# rCSL_rtc_001 register map
Vendor: Texas Instruments
Peripheral module from a debugger description file (folder OMAPL138_C6748).
Registers are 32-bit, access not given, reset 0x0 unless marked. A register's access mark holds for its fields unless they carry their own. Offsets are as the file gives them; lines under a group give offsets from that group; [hi:lo] are bit positions; {n}, {i} and the like mark numbered series; 'fields as' and 'values as' point back to an identical list; <NAME> marks a mode.

## RTC
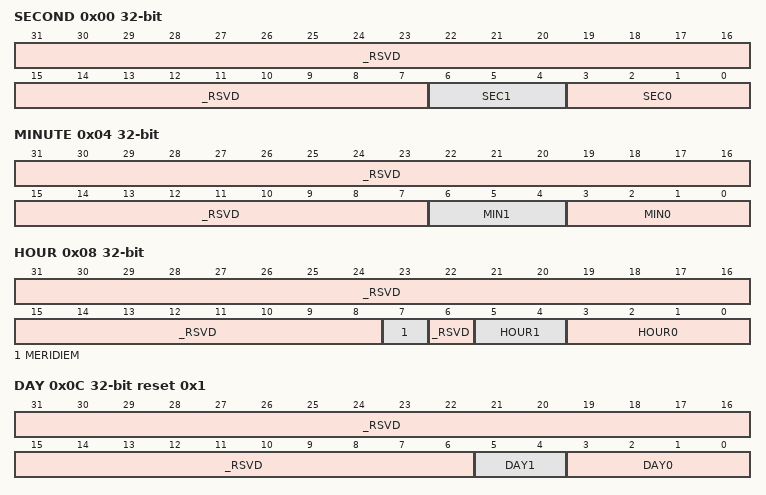
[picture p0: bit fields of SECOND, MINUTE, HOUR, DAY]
0x00 SECOND — Seconds Register
  [31:7] _RSVD — (access N)
  [6:4] SEC1 rw — 2nd digit of seconds
  [3:0] SEC0 rw — 1st digit of seconds
0x04 MINUTE — Minutes Register
  [31:7] _RSVD — (access N)
  [6:4] MIN1 rw — 2nd digit of minutes
  [3:0] MIN0 rw — 1st digit of minutes
0x08 HOUR — Hours Register
  [31:8] _RSVD — (access N)
  [7] MERIDIEM rw — PM or AM when PM_AM enabled
    0=AM; 1=PM
  [6] _RSVD — (access N)
  [5:4] HOUR1 rw — 2nd digit of hours
  [3:0] HOUR0 rw — 1st digit of hours
0x0C DAY reset 0x1 — Days Register
  [31:6] _RSVD — (access N)
  [5:4] DAY1 rw — 2nd digit of days
  [3:0] DAY0 rw — 1st digit of days
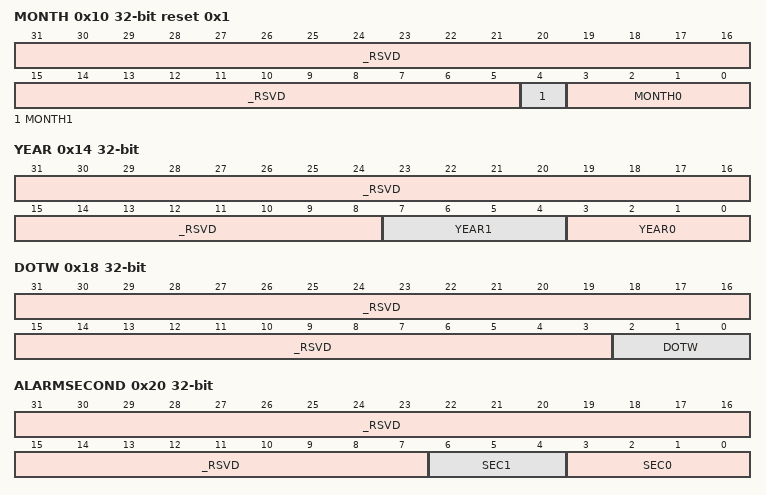
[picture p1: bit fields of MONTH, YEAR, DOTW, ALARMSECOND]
0x10 MONTH reset 0x1 — Months Register
  [31:5] _RSVD — (access N)
  [4] MONTH1 rw — 2nd digit of months
  [3:0] MONTH0 rw — 1st digit of months
0x14 YEAR — Years Register
  [31:8] _RSVD — (access N)
  [7:4] YEAR1 rw — 2nd digit of years
  [3:0] YEAR0 rw — 1st digit of years
0x18 DOTW — Weeks Register
  [31:3] _RSVD — (access N)
  [2:0] DOTW rw — 1st digit of day in week (SUN=0, SAT=6)
    0=SUN; 1=MON; 2=TUE; 3=WED; 4=THU; 5=FRI; 6=SAT
0x20 ALARMSECOND — Alarm Seconds Register
  fields as SECOND
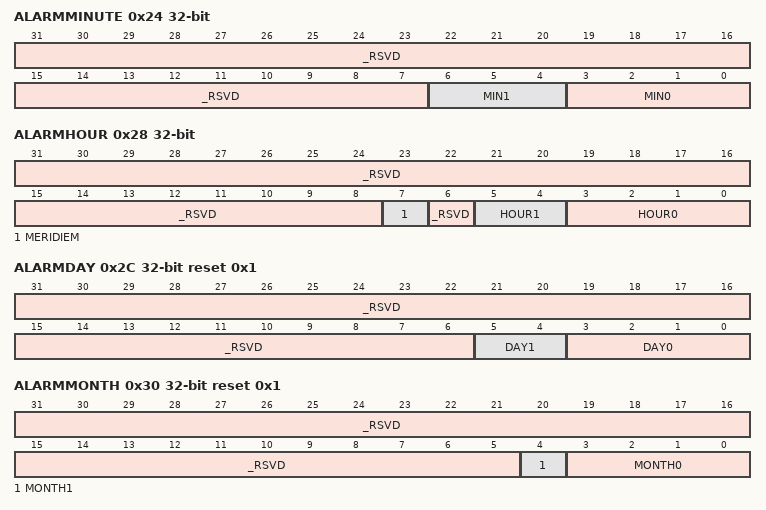
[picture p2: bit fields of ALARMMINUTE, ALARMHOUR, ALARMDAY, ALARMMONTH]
0x24 ALARMMINUTE — Alarm Minutes Register
  fields as MINUTE
0x28 ALARMHOUR — Alarm Hours Register
  [31:8] _RSVD — (access N)
  [7] MERIDIEM rw — AM or PM when PM_AM enabled
    0=AM; 1=PM
  [6] _RSVD — (access N)
  [5:4] HOUR1 rw — 2nd digit of hours
  [3:0] HOUR0 rw — 1st digit of hours
0x2C ALARMDAY reset 0x1 — Alarm Days Register
  [31:6] _RSVD — (access N)
  [5:4] DAY1 rw — 2nd digit for days
  [3:0] DAY0 rw — 1st digit for days
0x30 ALARMMONTH reset 0x1 — Alarm Months Register
  fields as MONTH
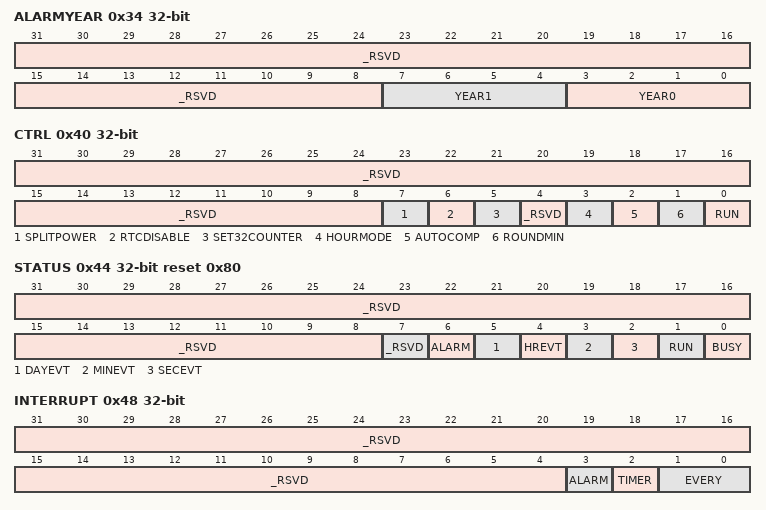
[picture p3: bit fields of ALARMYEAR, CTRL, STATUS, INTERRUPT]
0x34 ALARMYEAR — Alarm Years Register
  fields as YEAR
0x40 CTRL — RTC Control Register
  [31:8] _RSVD — (access N)
  [7] SPLITPOWER wo — Always reads 0. Use split power.
    0=DISABLE; 1=ENABLE
  [6] RTCDISABLE rw — Disable RTC
    0=ENABLE; 1=DISABLE
  [5] SET32COUNTER rw — Set 32kHz counter with comp value
    0=DISABLE; 1=ENABLE
  [4] _RSVD — Enable testmode (access N)
  [3] HOURMODE rw — Enable 12hr mode
    0=24HR; 1=12HR
  [2] AUTOCOMP rw — Enable auto-compensation
    0=DISABLE; 1=ENABLE
  [1] ROUNDMIN rw — Round to closest minute (ROUND_30S in doc)
    0=DISABLE; 1=ENABLE
  [0] RUN rw — Run RTC
    0=STOP; 1=RUN
0x44 STATUS reset 0x80 — RTC Status Register
  [31:8] _RSVD — (access N)
  [7] _RSVD — Indicates that the RTC module lost power; clear with 1 (access N)
  [6] ALARM rw — Indicates that an alarm interrupt has been generated
    0=INACTIVE; 1=ACTIVE
  [5] DAYEVT ro — One day event has occurred
    0=INACTIVE; 1=ACTIVE
  [4] HREVT ro — One hour event has occurred
    0=INACTIVE; 1=ACTIVE
  [3] MINEVT ro — One minute event has occurred
    0=INACTIVE; 1=ACTIVE
  [2] SECEVT ro — One second event has occurred
    0=INACTIVE; 1=ACTIVE
  [1] RUN ro — Run/Stop status
    0=STOP; 1=RUN
  [0] BUSY ro — Busy status
    0=FREE; 1=BUSY
0x48 INTERRUPT — RTC Interrupts Register
  [31:4] _RSVD — (access N)
  [3] ALARM rw — Enable one interrupt when alarm value is reached
    0=DISABLE; 1=ENABLE
  [2] TIMER rw — Enable periodic interrupt
    0=DISABLE; 1=ENABLE
  [1:0] EVERY rw — Interrupt period
    0=SECOND; 1=MINUTE; 2=HOUR; 3=DAY
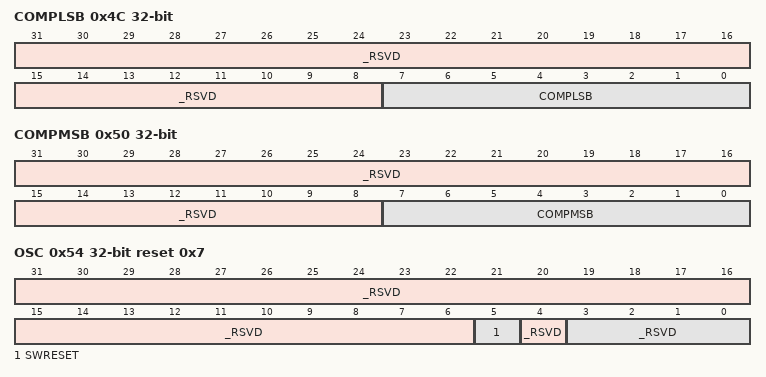
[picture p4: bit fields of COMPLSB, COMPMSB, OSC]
0x4C COMPLSB — RTC Compensation LSB Register
  [31:8] _RSVD — (access N)
  [7:0] COMPLSB rw — Number of 32kHz periods to be added [subtracted by twos complement] every hour
0x50 COMPMSB — RTC Compensation LSB Register
  [31:8] _RSVD — (access N)
  [7:0] COMPMSB rw — Number of 32kHz periods to be added [subtracted by twos complement] every hour
0x54 OSC reset 0x7 — RTC Oscillator Resistance Register
  [31:6] _RSVD — (access N)
  [5] SWRESET rw — Software reset bit
    0=NOTINRESET; 1=RESET
  [4] _RSVD — 32kHz oscillator powerdown (access N)
  [3:0] _RSVD — Value of oscillator resistance (access N)
{0x60+4i} SCRATCH{i} rw (i=0..2) — RTC Scratch{i} Register
  [31:0] SCRATCH{i} — Scratch register available to proram
0x6C KICK0 wo
  [31:0] KICK0 — Unlocks KICK0 data & kicker with 0x83E70B13
0x70 KICK1 wo
  [31:0] KICK1 — Unlocks KICK1 data & kicker with 0x95A4F1E0
